# MSP430FR5969 register map
Vendor: msp430gen; File version: v0.4.0-24-gb954137
Registers are 16-bit, read-write, reset 0x0 unless marked. A register's access mark holds for its fields unless they carry their own. Offsets are from the block's base; [hi:lo] are bit positions; {n}, {i} and the like mark numbered series.

## ADC12
Base 0x00000800
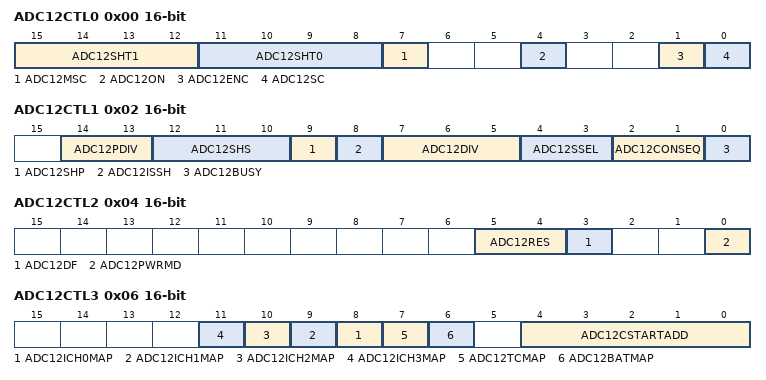
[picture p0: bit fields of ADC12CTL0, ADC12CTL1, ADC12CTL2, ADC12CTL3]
0x00 ADC12CTL0 — ADC12 B Control 0
  [15:12] ADC12SHT1 — ADC12 Sample Hold 1 Select Bit: 0
    {v}=ADC12 Sample Hold 1 Select Bit: {v} (v=0..15)
  [11:8] ADC12SHT0 — ADC12 Sample Hold 0 Select Bit: 0
    {v}=ADC12 Sample Hold 0 Select Bit: {v} (v=0..15)
  [7] ADC12MSC — ADC12 Multiple SampleConversion
  [4] ADC12ON — ADC12 On/enable
  [1] ADC12ENC — ADC12 Enable Conversion
  [0] ADC12SC — ADC12 Start Conversion
0x02 ADC12CTL1 — ADC12 B Control 1
  [14:13] ADC12PDIV — ADC12 Predivider Bit: 0
    {v}=ADC12 Clock predivider Select {v} (v=0..3)
  [12:10] ADC12SHS — ADC12 Sample/Hold Source Bit: 0
    {v}=ADC12 Sample/Hold Source: {v} (v=0..7)
  [9] ADC12SHP — ADC12 Sample/Hold Pulse Mode
  [8] ADC12ISSH — ADC12 Invert Sample Hold Signal
  [7:5] ADC12DIV — ADC12 Clock Divider Select Bit: 0
    {v}=ADC12 Clock Divider Select: {v} (v=0..7)
  [4:3] ADC12SSEL — ADC12 Clock Source Select Bit: 0
    {v}=ADC12 Clock Source Select: {v} (v=0..3)
  [2:1] ADC12CONSEQ — ADC12 Conversion Sequence Select Bit: 0
    {v}=ADC12 Conversion Sequence Select: {v} (v=0..3)
  [0] ADC12BUSY
0x04 ADC12CTL2 — ADC12 B Control 2
  [5:4] ADC12RES — ADC12 Resolution Bit: 0
    0=ADC12+ Resolution : 8 Bit; 1=ADC12+ Resolution : 10 Bit; 2=ADC12+ Resolution : 12 Bit; 3=ADC12+ Resolution : reserved
  [3] ADC12DF — ADC12 Data Format
  [0] ADC12PWRMD — ADC12 Power Mode
0x06 ADC12CTL3 — ADC12 B Control 3
  [n+8] ADC12ICH{n}MAP (n=0..3) — ADC12 Internal Channel {n} select
  [7] ADC12TCMAP — ADC12 Internal TempSensor select
  [6] ADC12BATMAP — ADC12 Internal AVCC/2 select
  [4:0] ADC12CSTARTADD — ADC12 Conversion Start Address Bit: 0
    {v}=ADC12 Conversion Start Address: {v} (v=0..31)
0x08 ADC12LO — ADC12 B Window Comparator High Threshold
0x0A ADC12HI — ADC12 B Window Comparator High Threshold
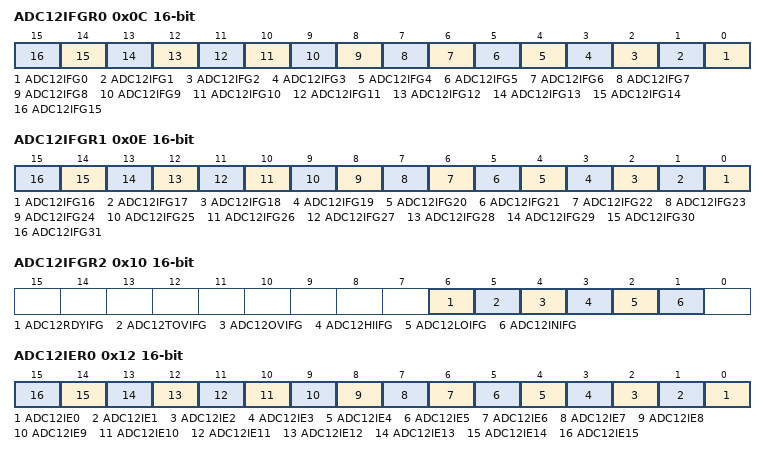
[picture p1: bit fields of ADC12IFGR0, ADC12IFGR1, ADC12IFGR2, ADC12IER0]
0x0C ADC12IFGR0 — ADC12 B Interrupt Flag 0
  [n] ADC12IFG{n} (n=0..15) — ADC12 Memory {n} Interrupt Flag
0x0E ADC12IFGR1 — ADC12 B Interrupt Flag 1
  [n-16] ADC12IFG{n} (n=16..31) — ADC12 Memory {n} Interrupt Flag
0x10 ADC12IFGR2 — ADC12 B Interrupt Flag 2
  [6] ADC12RDYIFG — ADC12 local buffered reference ready interrupt Flag
  [5] ADC12TOVIFG — ADC12 Timer Overflow interrupt Flag
  [4] ADC12OVIFG — ADC12 ADC12MEMx Overflow interrupt Flag
  [3] ADC12HIIFG — ADC12 Interrupt Flag for upper threshold of the Window comparator
  [2] ADC12LOIFG — ADC12 Interrupt Flag for lower threshold of the Window comparator
  [1] ADC12INIFG — ADC12 Interrupt Flag for the inside of window of the Window comparator
0x12 ADC12IER0 — ADC12 B Interrupt Enable 0
  [n] ADC12IE{n} (n=0..15) — ADC12 Memory {n} Interrupt Enable
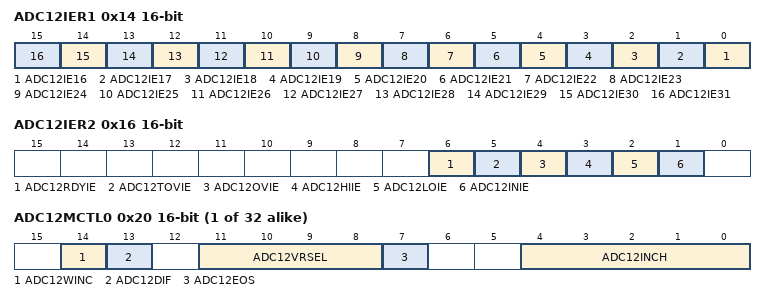
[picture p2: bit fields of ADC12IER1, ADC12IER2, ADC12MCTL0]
0x14 ADC12IER1 — ADC12 B Interrupt Enable 1
  [n-16] ADC12IE{n} (n=16..31) — ADC12 Memory {n} Interrupt Enable
0x16 ADC12IER2 — ADC12 B Interrupt Enable 2
  [6] ADC12RDYIE — ADC12 local buffered reference ready interrupt enable
  [5] ADC12TOVIE — ADC12 Timer Overflow interrupt enable
  [4] ADC12OVIE — ADC12 ADC12MEMx Overflow interrupt enable
  [3] ADC12HIIE — ADC12 Interrupt enable for upper threshold of the Window comparator
  [2] ADC12LOIE — ADC12 Interrupt enable for lower threshold of the Window comparator
  [1] ADC12INIE — ADC12 Interrupt enable for the inside of window of the Window comparator
0x18 ADC12IV — ADC12 B Interrupt Vector Word
{0x20+2i} ADC12MCTL{i} (i=0..31) — ADC12 Memory Control {i}
  [14] ADC12WINC — ADC12 Comparator window enable
  [13] ADC12DIF — ADC12 Differential mode (only for even Registers)
  [11:8] ADC12VRSEL — ADC12 VR Select Bit 0
    {v}=ADC12 Select Reference {v} (v=0..15)
  [7] ADC12EOS — ADC12 End of Sequence
  [4:0] ADC12INCH — ADC12 Input Channel Select Bit 0
    {v}=ADC12 Input Channel {v} (v=0..31)
{0x60+2i} ADC12MEM{i} (i=0..31) — ADC12 Conversion Memory {i}
